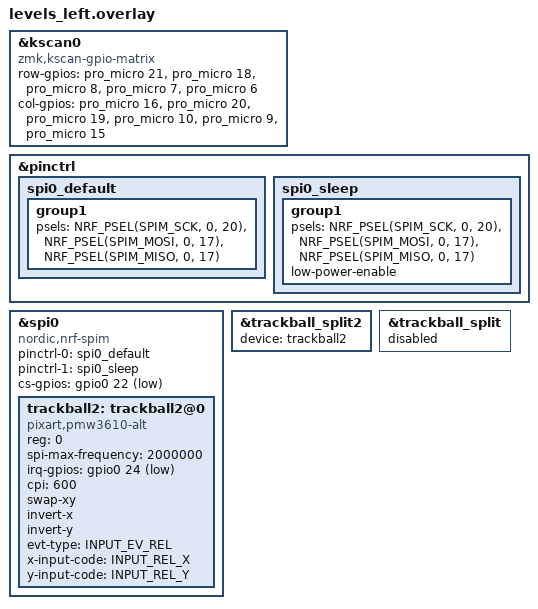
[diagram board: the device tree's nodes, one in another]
// vim: set ft=dts:
#include "levels.dtsi"
#include <dt-bindings/zmk/input_transform.h>

&kscan0 {
  compatible = "zmk,kscan-gpio-matrix";
  row-gpios
    = <&pro_micro 21 (GPIO_ACTIVE_HIGH | GPIO_PULL_DOWN)>
    , <&pro_micro 18 (GPIO_ACTIVE_HIGH | GPIO_PULL_DOWN)>
    , <&pro_micro 8  (GPIO_ACTIVE_HIGH | GPIO_PULL_DOWN)>
    , <&pro_micro 7  (GPIO_ACTIVE_HIGH | GPIO_PULL_DOWN)>
    , <&pro_micro 6  (GPIO_ACTIVE_HIGH | GPIO_PULL_DOWN)>
    ;
  col-gpios
    = <&pro_micro 16 GPIO_ACTIVE_HIGH>
    , <&pro_micro 20 GPIO_ACTIVE_HIGH>
    , <&pro_micro 19 GPIO_ACTIVE_HIGH>
    , <&pro_micro 10 GPIO_ACTIVE_HIGH>
    , <&pro_micro 9  GPIO_ACTIVE_HIGH>
    , <&pro_micro 15 GPIO_ACTIVE_HIGH>
    ;
};

&pinctrl {
  spi0_default: spi0_default {
    group1 {
      psels
        = <NRF_PSEL(SPIM_SCK,  0, 20)>
        , <NRF_PSEL(SPIM_MOSI, 0, 17)>
        , <NRF_PSEL(SPIM_MISO, 0, 17)>
        ;
    };
  };
  spi0_sleep: spi0_sleep {
    group1 {
      psels
        = <NRF_PSEL(SPIM_SCK,  0, 20)>
        , <NRF_PSEL(SPIM_MOSI, 0, 17)>
        , <NRF_PSEL(SPIM_MISO, 0, 17)>
        ;
      low-power-enable;
    };
  };
};

&spi0 {
  compatible = "nordic,nrf-spim";
  status = "okay";
  pinctrl-0 = <&spi0_default>;
  pinctrl-1 = <&spi0_sleep>;
  pinctrl-names = "default", "sleep";
  cs-gpios = <&gpio0 22 GPIO_ACTIVE_LOW>;

  trackball2: trackball2@0 {
    status = "okay";
    compatible = "pixart,pmw3610-alt";
    reg = <0>;
    spi-max-frequency = <2000000>;
    irq-gpios = <&gpio0 24 (GPIO_ACTIVE_LOW | GPIO_PULL_UP)>;
    cpi = <600>;
    swap-xy;
    invert-x;
    invert-y;
    evt-type = <INPUT_EV_REL>;
    x-input-code = <INPUT_REL_X>;
    y-input-code = <INPUT_REL_Y>;
  };
};

&trackball_split2 {
  device = <&trackball2>;
};

&trackball_split {
  status = "disabled";
};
